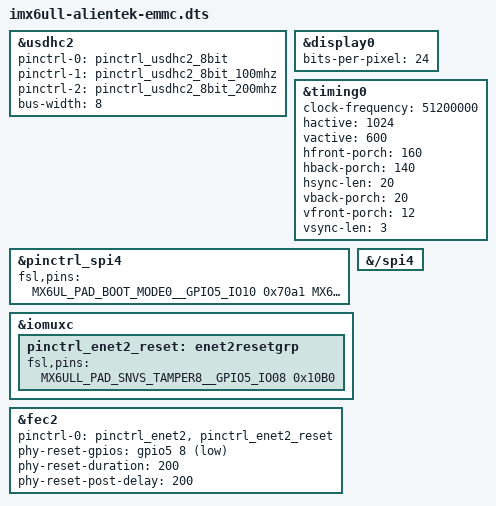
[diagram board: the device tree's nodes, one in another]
/*
 * Copyright 2019 NXP
 *
 * This program is free software; you can redistribute it and/or
 * modify it under the terms of the GNU General Public License
 * as published by the Free Software Foundation; either version 2
 * of the License, or (at your option) any later version.
 */

#include "imx6ull-14x14-evk.dts"

&usdhc2 {
	pinctrl-names = "default", "state_100mhz", "state_200mhz";
	pinctrl-0 = <&pinctrl_usdhc2_8bit>;
	pinctrl-1 = <&pinctrl_usdhc2_8bit_100mhz>;
	pinctrl-2 = <&pinctrl_usdhc2_8bit_200mhz>;
	bus-width = <8>;
};

/* 配置lcd */
&display0 {
	bits-per-pixel = <24>;
};

&timing0 {
	clock-frequency = <51200000>;
	hactive = <1024>;
	vactive = <600>;
	hfront-porch = <160>;
	hback-porch = <140>;
	hsync-len = <20>;
	vback-porch = <20>;
	vfront-porch = <12>;
	vsync-len = <3>;
};

/* 移除对网络复位引脚的占用 */
&pinctrl_spi4 {
	fsl,pins = <
		MX6UL_PAD_BOOT_MODE0__GPIO5_IO10	0x70a1
		MX6UL_PAD_BOOT_MODE1__GPIO5_IO11	0x70a1
		MX6UL_PAD_SNVS_TAMPER7__GPIO5_IO07	0x70a1 
		/* MX6UL_PAD_SNVS_TAMPER8__GPIO5_IO08	0x80000000 */
	>;
};

/* 移除对网络复位引脚的占用 */
&{/spi4} {
	/delete-property/ pinctrl-assert-gpios;
};

/* 添加复位引脚复用 */
&iomuxc {
	pinctrl_enet2_reset: enet2resetgrp {
		fsl,pins = <MX6ULL_PAD_SNVS_TAMPER8__GPIO5_IO08 0x10B0>;
	};
};

/* fec2使用复位引脚 */
&fec2 {	
	pinctrl-0 = <&pinctrl_enet2 &pinctrl_enet2_reset>;
	phy-reset-gpios = <&gpio5 8 GPIO_ACTIVE_LOW>;
	phy-reset-duration = <200>;
	phy-reset-post-delay = <200>;
};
